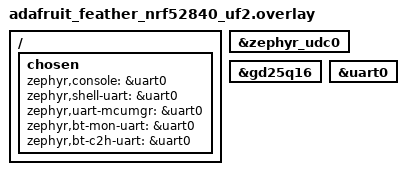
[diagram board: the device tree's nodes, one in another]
/ {
	chosen {
		zephyr,console = &uart0;
		zephyr,shell-uart = &uart0;
		zephyr,uart-mcumgr = &uart0;
		zephyr,bt-mon-uart = &uart0;
		zephyr,bt-c2h-uart = &uart0;
	};
};

&zephyr_udc0 {
	/delete-node/ board_cdc_acm_uart;
};


&gd25q16 {
	/delete-node/ partitions;
};

&uart0 {
    status = "okay";
};

#include "../app.overlay"
